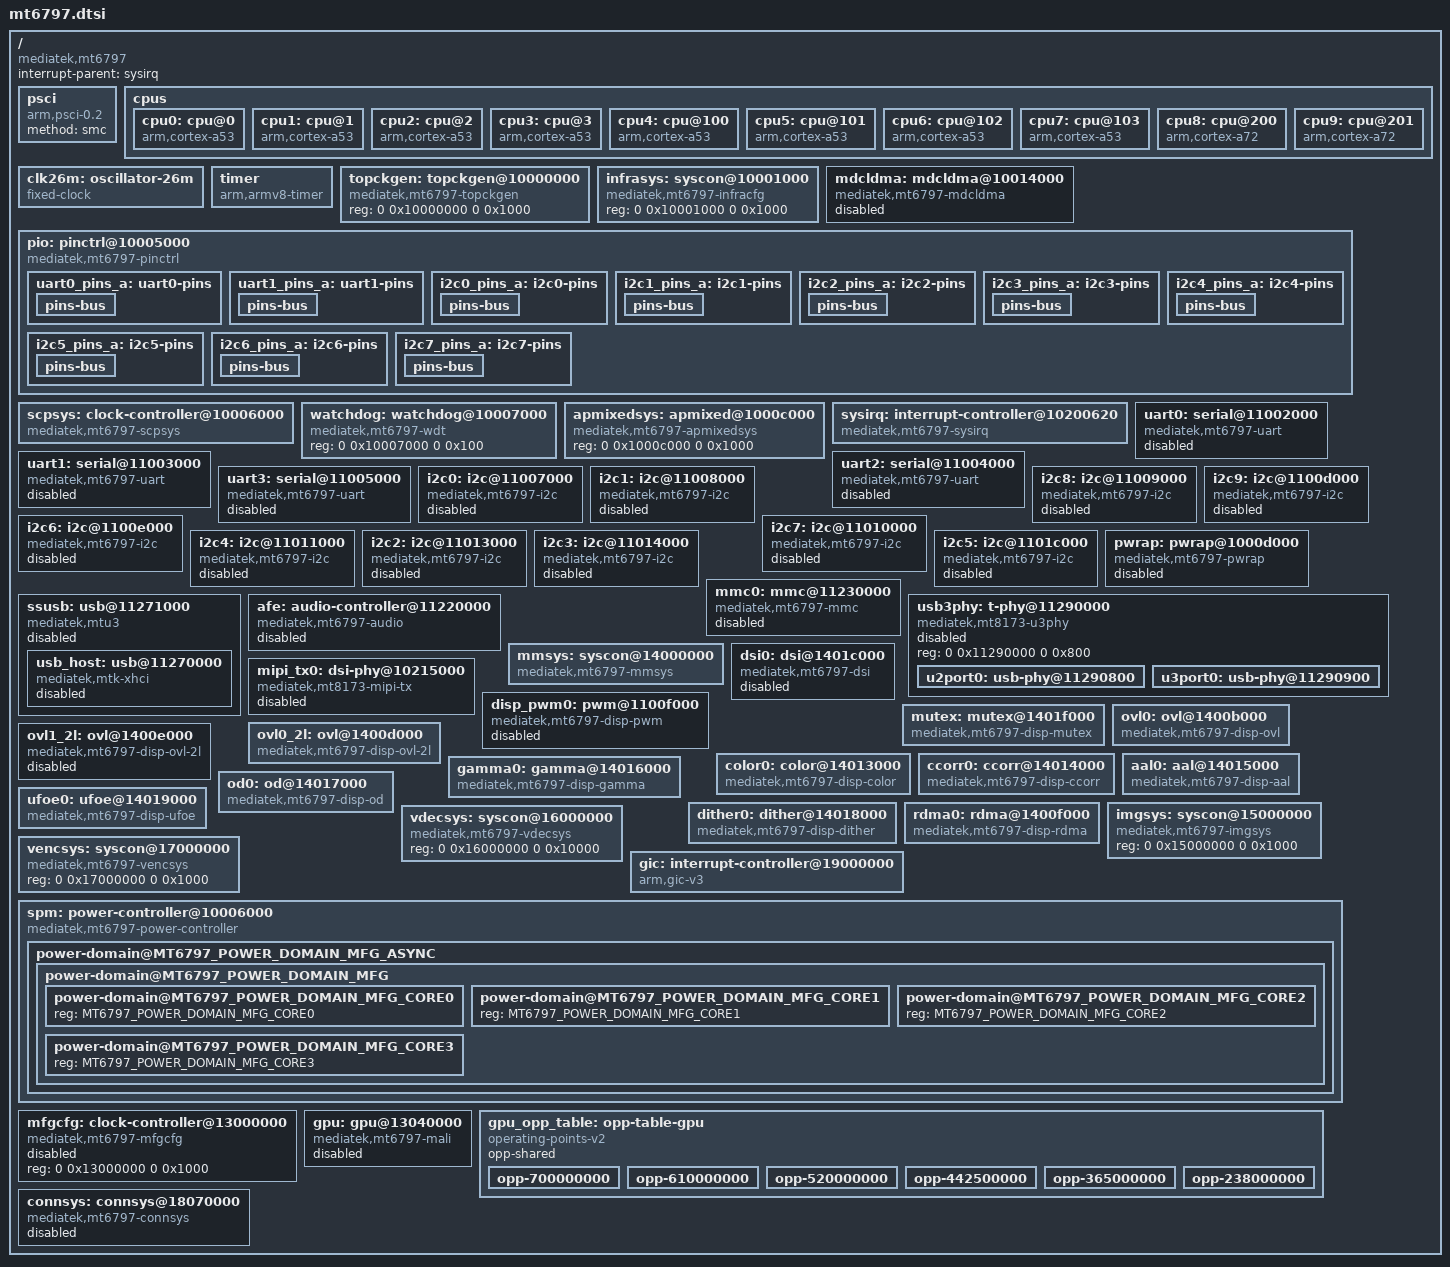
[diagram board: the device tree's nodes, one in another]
// SPDX-License-Identifier: GPL-2.0
/*
 * Copyright (c) 2017 MediaTek Inc.
 * Author: Mars.C <mars.cheng@mediatek.com>
 */

#include <dt-bindings/clock/mediatek,mt6797-mfgcfg.h>
#include <dt-bindings/clock/mt6797-clk.h>
#include <dt-bindings/interrupt-controller/irq.h>
#include <dt-bindings/interrupt-controller/arm-gic.h>
#include <dt-bindings/pinctrl/mt6797-pinfunc.h>
#include <dt-bindings/phy/phy.h>
#include <dt-bindings/power/mt6797-power.h>
#include <dt-bindings/reset/mt6797-resets.h>

/ {
	compatible = "mediatek,mt6797";
	interrupt-parent = <&sysirq>;
	#address-cells = <2>;
	#size-cells = <2>;

	psci {
		compatible = "arm,psci-0.2";
		method = "smc";
	};

	cpus {
		#address-cells = <1>;
		#size-cells = <0>;

		cpu0: cpu@0 {
			device_type = "cpu";
			compatible = "arm,cortex-a53";
			enable-method = "psci";
			reg = <0x000>;
		};

		cpu1: cpu@1 {
			device_type = "cpu";
			compatible = "arm,cortex-a53";
			enable-method = "psci";
			reg = <0x001>;
		};

		cpu2: cpu@2 {
			device_type = "cpu";
			compatible = "arm,cortex-a53";
			enable-method = "psci";
			reg = <0x002>;
		};

		cpu3: cpu@3 {
			device_type = "cpu";
			compatible = "arm,cortex-a53";
			enable-method = "psci";
			reg = <0x003>;
		};

		cpu4: cpu@100 {
			device_type = "cpu";
			compatible = "arm,cortex-a53";
			enable-method = "psci";
			reg = <0x100>;
		};

		cpu5: cpu@101 {
			device_type = "cpu";
			compatible = "arm,cortex-a53";
			enable-method = "psci";
			reg = <0x101>;
		};

		cpu6: cpu@102 {
			device_type = "cpu";
			compatible = "arm,cortex-a53";
			enable-method = "psci";
			reg = <0x102>;
		};

		cpu7: cpu@103 {
			device_type = "cpu";
			compatible = "arm,cortex-a53";
			enable-method = "psci";
			reg = <0x103>;
		};

		cpu8: cpu@200 {
			device_type = "cpu";
			compatible = "arm,cortex-a72";
			enable-method = "psci";
			reg = <0x200>;
		};

		cpu9: cpu@201 {
			device_type = "cpu";
			compatible = "arm,cortex-a72";
			enable-method = "psci";
			reg = <0x201>;
		};
	};

	clk26m: oscillator-26m {
		compatible = "fixed-clock";
		#clock-cells = <0>;
		clock-frequency = <26000000>;
		clock-output-names = "clk26m";
	};

	timer {
		compatible = "arm,armv8-timer";
		interrupt-parent = <&gic>;
		interrupts = <GIC_PPI 13 IRQ_TYPE_LEVEL_LOW>,
			     <GIC_PPI 14 IRQ_TYPE_LEVEL_LOW>,
			     <GIC_PPI 11 IRQ_TYPE_LEVEL_LOW>,
			     <GIC_PPI 10 IRQ_TYPE_LEVEL_LOW>;
	};

	topckgen: topckgen@10000000 {
		compatible = "mediatek,mt6797-topckgen";
		reg = <0 0x10000000 0 0x1000>;
		#clock-cells = <1>;
	};

	infrasys: syscon@10001000 {
		compatible = "mediatek,mt6797-infracfg", "syscon";
		reg = <0 0x10001000 0 0x1000>;
		#clock-cells = <1>;
		#reset-cells = <1>;
	};

	/*
	 * MD1 cellular modem: CLDMA DMA rings plus the CCIF doorbell.
	 * Register windows from the vendor 3.18 mt6797 DTS: CLDMA AO
	 * 0x10014000/0x10015000, CLDMA PD 0x10219000/0x1021a000, CCIF
	 * 0x10209000/0x1020a000, IRQ 265 (CLDMA), 147 (CCIF) and 266
	 * (MD watchdog).
	 */
	mdcldma: mdcldma@10014000 {
		compatible = "mediatek,mt6797-mdcldma";
		reg = <0 0x10014000 0 0x1e00>,	/* AP CLDMA AO */
		      <0 0x10015000 0 0x1e00>,	/* MD CLDMA AO */
		      <0 0x10219000 0 0x1e00>,	/* AP CLDMA PD */
		      <0 0x1021a000 0 0x1e00>,	/* MD CLDMA PD */
		      <0 0x10209000 0 0x1000>,	/* AP CCIF */
		      <0 0x1020a000 0 0x1000>;	/* MD CCIF */
		interrupts = <GIC_SPI 265 IRQ_TYPE_LEVEL_HIGH>,
			     <GIC_SPI 147 IRQ_TYPE_LEVEL_LOW>,
			     <GIC_SPI 266 IRQ_TYPE_EDGE_FALLING>;
		mediatek,md_id = <0>;
		mediatek,cldma_capability = <6>;
		mediatek,md_smem_size = <0x100000>;
		clocks = <&infrasys CLK_INFRA_CCIF_AP>,
			 <&infrasys CLK_INFRA_CCIF_MD>,
			 <&infrasys CLK_INFRA_CLDMA>;
		clock-names = "ccif-ap", "ccif-md", "cldma";
		status = "disabled";
	};

	pio: pinctrl@10005000 {
		compatible = "mediatek,mt6797-pinctrl";
		reg = <0 0x10005000 0 0x1000>,
		      <0 0x10002000 0 0x400>,
		      <0 0x10002400 0 0x400>,
		      <0 0x10002800 0 0x400>,
		      <0 0x10002C00 0 0x400>,
		      <0 0x1000b000 0 0x1000>;
		reg-names = "gpio", "iocfgl", "iocfgb",
			    "iocfgr", "iocfgt", "eint";
		gpio-controller;
		#gpio-cells = <2>;
		gpio-ranges = <&pio 0 0 262>;
		interrupt-controller;
		#interrupt-cells = <2>;
		#address-cells = <0>;
		interrupts = <GIC_SPI 170 IRQ_TYPE_LEVEL_HIGH>;

		uart0_pins_a: uart0-pins {
			pins-bus {
				pinmux = <MT6797_GPIO234__FUNC_UTXD0>,
					 <MT6797_GPIO235__FUNC_URXD0>;
			};
		};

		uart1_pins_a: uart1-pins {
			pins-bus {
				pinmux = <MT6797_GPIO232__FUNC_URXD1>,
					 <MT6797_GPIO233__FUNC_UTXD1>;
			};
		};

		i2c0_pins_a: i2c0-pins {
			pins-bus {
				pinmux = <MT6797_GPIO37__FUNC_SCL0_0>,
					 <MT6797_GPIO38__FUNC_SDA0_0>;
			};
		};

		i2c1_pins_a: i2c1-pins {
			pins-bus {
				pinmux = <MT6797_GPIO55__FUNC_SCL1_0>,
					 <MT6797_GPIO56__FUNC_SDA1_0>;
			};
		};

		i2c2_pins_a: i2c2-pins {
			pins-bus {
				pinmux = <MT6797_GPIO96__FUNC_SCL2_0>,
					 <MT6797_GPIO95__FUNC_SDA2_0>;
			};
		};

		i2c3_pins_a: i2c3-pins {
			pins-bus {
				pinmux = <MT6797_GPIO75__FUNC_SDA3_0>,
					 <MT6797_GPIO74__FUNC_SCL3_0>;
			};
		};

		i2c4_pins_a: i2c4-pins {
			pins-bus {
				pinmux = <MT6797_GPIO238__FUNC_SDA4_0>,
					 <MT6797_GPIO239__FUNC_SCL4_0>;
			};
		};

		i2c5_pins_a: i2c5-pins {
			pins-bus {
				pinmux = <MT6797_GPIO240__FUNC_SDA5_0>,
					 <MT6797_GPIO241__FUNC_SCL5_0>;
			};
		};

		i2c6_pins_a: i2c6-pins {
			pins-bus {
				pinmux = <MT6797_GPIO152__FUNC_SDA6_0>,
					 <MT6797_GPIO151__FUNC_SCL6_0>;
			};
		};

		i2c7_pins_a: i2c7-pins {
			pins-bus {
				pinmux = <MT6797_GPIO154__FUNC_SDA7_0>,
					 <MT6797_GPIO153__FUNC_SCL7_0>;
			};
		};
	};

	/*
	 * Legacy MT6797 clock/power-controller node: not a genpd provider
	 * (that is "spm", mt6797-power-controller, further down this file),
	 * it only backs the power-domain-cells phandle on mmsys. Unit
	 * address renamed so it no longer collides with the SPM genpd node.
	 */
	scpsys: clock-controller@10006000 {
		compatible = "mediatek,mt6797-scpsys";
		#power-domain-cells = <1>;
		reg = <0 0x10006000 0 0x1000>;
		clocks = <&topckgen CLK_TOP_MUX_MFG>,
			 <&topckgen CLK_TOP_MUX_MM>,
			 <&topckgen CLK_TOP_MUX_VDEC>;
		clock-names = "mfg", "mm", "vdec";
		infracfg = <&infrasys>;
	};

	watchdog: watchdog@10007000 {
		compatible = "mediatek,mt6797-wdt", "mediatek,mt6589-wdt";
		reg = <0 0x10007000 0 0x100>;
	};

	apmixedsys: apmixed@1000c000 {
		compatible = "mediatek,mt6797-apmixedsys";
		reg = <0 0x1000c000 0 0x1000>;
		#clock-cells = <1>;
	};

	sysirq: interrupt-controller@10200620 {
		compatible = "mediatek,mt6797-sysirq",
			     "mediatek,mt6577-sysirq";
		interrupt-controller;
		#interrupt-cells = <3>;
		interrupt-parent = <&gic>;
		reg = <0 0x10220620 0 0x20>,
		      <0 0x10220690 0 0x10>;
	};

	uart0: serial@11002000 {
		compatible = "mediatek,mt6797-uart",
			     "mediatek,mt6577-uart";
		reg = <0 0x11002000 0 0x400>;
		interrupts = <GIC_SPI 91 IRQ_TYPE_LEVEL_LOW>;
		clocks = <&infrasys CLK_INFRA_UART0>,
			 <&infrasys CLK_INFRA_AP_DMA>;
		clock-names = "baud", "bus";
		status = "disabled";
	};

	uart1: serial@11003000 {
		compatible = "mediatek,mt6797-uart",
			     "mediatek,mt6577-uart";
		reg = <0 0x11003000 0 0x400>;
		interrupts = <GIC_SPI 92 IRQ_TYPE_LEVEL_LOW>;
		clocks = <&infrasys CLK_INFRA_UART1>,
			 <&infrasys CLK_INFRA_AP_DMA>;
		clock-names = "baud", "bus";
		status = "disabled";
	};

	uart2: serial@11004000 {
		compatible = "mediatek,mt6797-uart",
			     "mediatek,mt6577-uart";
		reg = <0 0x11004000 0 0x400>;
		interrupts = <GIC_SPI 93 IRQ_TYPE_LEVEL_LOW>;
		clocks = <&infrasys CLK_INFRA_UART2>,
			 <&infrasys CLK_INFRA_AP_DMA>;
		clock-names = "baud", "bus";
		status = "disabled";
	};

	uart3: serial@11005000 {
		compatible = "mediatek,mt6797-uart",
			     "mediatek,mt6577-uart";
		reg = <0 0x11005000 0 0x400>;
		interrupts = <GIC_SPI 94 IRQ_TYPE_LEVEL_LOW>;
		clocks = <&infrasys CLK_INFRA_UART3>,
			 <&infrasys CLK_INFRA_AP_DMA>;
		clock-names = "baud", "bus";
		status = "disabled";
	};

	i2c0: i2c@11007000 {
		compatible = "mediatek,mt6797-i2c",
			     "mediatek,mt6577-i2c";
		reg = <0 0x11007000 0 0x1000>,
		      <0 0x11000100 0 0x80>;
		interrupts = <GIC_SPI 84 IRQ_TYPE_LEVEL_LOW>;
		clocks = <&infrasys CLK_INFRA_I2C0>,
			 <&infrasys CLK_INFRA_AP_DMA>;
		clock-names = "main", "dma";
		clock-div = <10>;
		#address-cells = <1>;
		#size-cells = <0>;
		status = "disabled";
	};

	i2c1: i2c@11008000 {
		compatible = "mediatek,mt6797-i2c",
			     "mediatek,mt6577-i2c";
		reg = <0 0x11008000 0 0x1000>,
		      <0 0x11000180 0 0x80>;
		interrupts = <GIC_SPI 85 IRQ_TYPE_LEVEL_LOW>;
		clocks = <&infrasys CLK_INFRA_I2C1>,
			 <&infrasys CLK_INFRA_AP_DMA>;
		clock-names = "main", "dma";
		clock-div = <10>;
		#address-cells = <1>;
		#size-cells = <0>;
		status = "disabled";
	};

	i2c8: i2c@11009000 {
		compatible = "mediatek,mt6797-i2c",
			     "mediatek,mt6577-i2c";
		reg = <0 0x11009000 0 0x1000>,
		      <0 0x11000200 0 0x80>;
		interrupts = <GIC_SPI 86 IRQ_TYPE_LEVEL_LOW>;
		clocks = <&infrasys CLK_INFRA_I2C2>,
			 <&infrasys CLK_INFRA_AP_DMA>,
			 <&infrasys CLK_INFRA_I2C2_ARB>;
		clock-names = "main", "dma", "arb";
		clock-div = <10>;
		#address-cells = <1>;
		#size-cells = <0>;
		status = "disabled";
	};

	i2c9: i2c@1100d000 {
		compatible = "mediatek,mt6797-i2c",
			     "mediatek,mt6577-i2c";
		reg = <0 0x1100d000 0 0x1000>,
		      <0 0x11000280 0 0x80>;
		interrupts = <GIC_SPI 87 IRQ_TYPE_LEVEL_LOW>;
		clocks = <&infrasys CLK_INFRA_I2C3>,
			 <&infrasys CLK_INFRA_AP_DMA>,
			 <&infrasys CLK_INFRA_I2C3_ARB>;
		clock-names = "main", "dma", "arb";
		clock-div = <10>;
		#address-cells = <1>;
		#size-cells = <0>;
		status = "disabled";
	};

	i2c6: i2c@1100e000 {
		compatible = "mediatek,mt6797-i2c",
			     "mediatek,mt6577-i2c";
		reg = <0 0x1100e000 0 0x1000>,
		      <0 0x11000500 0 0x80>;
		interrupts = <GIC_SPI 88 IRQ_TYPE_LEVEL_LOW>;
		clocks = <&infrasys CLK_INFRA_I2C_APPM>,
			 <&infrasys CLK_INFRA_AP_DMA>;
		clock-names = "main", "dma";
		clock-div = <10>;
		#address-cells = <1>;
		#size-cells = <0>;
		status = "disabled";
	};

	i2c7: i2c@11010000 {
		compatible = "mediatek,mt6797-i2c",
			     "mediatek,mt6577-i2c";
		reg = <0 0x11010000 0 0x1000>,
		      <0 0x11000580 0 0x80>;
		interrupts = <GIC_SPI 89 IRQ_TYPE_LEVEL_LOW>;
		clocks = <&infrasys CLK_INFRA_I2C_GPUPM>,
			 <&infrasys CLK_INFRA_AP_DMA>;
		clock-names = "main", "dma";
		clock-div = <10>;
		#address-cells = <1>;
		#size-cells = <0>;
		status = "disabled";
	};

	i2c4: i2c@11011000 {
		compatible = "mediatek,mt6797-i2c",
			     "mediatek,mt6577-i2c";
		reg = <0 0x11011000 0 0x1000>,
		      <0 0x11000300 0 0x80>;
		interrupts = <GIC_SPI 90 IRQ_TYPE_LEVEL_LOW>;
		clocks = <&infrasys CLK_INFRA_I2C4>,
			 <&infrasys CLK_INFRA_AP_DMA>;
		clock-names = "main", "dma";
		clock-div = <10>;
		#address-cells = <1>;
		#size-cells = <0>;
		status = "disabled";
	};

	i2c2: i2c@11013000 {
		compatible = "mediatek,mt6797-i2c",
			     "mediatek,mt6577-i2c";
		reg = <0 0x11013000 0 0x1000>,
		      <0 0x11000400 0 0x80>;
		interrupts = <GIC_SPI 95 IRQ_TYPE_LEVEL_LOW>;
		clocks = <&infrasys CLK_INFRA_I2C2_IMM>,
			 <&infrasys CLK_INFRA_AP_DMA>,
			 <&infrasys CLK_INFRA_I2C2_ARB>;
		clock-names = "main", "dma", "arb";
		clock-div = <10>;
		#address-cells = <1>;
		#size-cells = <0>;
		status = "disabled";
	};

	i2c3: i2c@11014000 {
		compatible = "mediatek,mt6797-i2c",
			     "mediatek,mt6577-i2c";
		reg = <0 0x11014000 0 0x1000>,
		      <0 0x11000480 0 0x80>;
		interrupts = <GIC_SPI 96 IRQ_TYPE_LEVEL_LOW>;
		clocks = <&infrasys CLK_INFRA_I2C3_IMM>,
			 <&infrasys CLK_INFRA_AP_DMA>,
			 <&infrasys CLK_INFRA_I2C3_ARB>;
		clock-names = "main", "dma", "arb";
		clock-div = <10>;
		#address-cells = <1>;
		#size-cells = <0>;
		status = "disabled";
	};

	i2c5: i2c@1101c000 {
		compatible = "mediatek,mt6797-i2c",
			     "mediatek,mt6577-i2c";
		reg = <0 0x1101c000 0 0x1000>,
		      <0 0x11000380 0 0x80>;
		interrupts = <GIC_SPI 83 IRQ_TYPE_LEVEL_LOW>;
		clocks = <&infrasys CLK_INFRA_I2C5>,
			 <&infrasys CLK_INFRA_AP_DMA>;
		clock-names = "main", "dma";
		clock-div = <10>;
		#address-cells = <1>;
		#size-cells = <0>;
		status = "disabled";
	};

	/*
	 * PMIC wrapper. MT6797 uses the same register layout as MT6755/MT6797
	 * (pwrap_mt6797 in the driver); the wrapper is brought up by LK, so
	 * Linux only needs the regmap for the MT6351 child.
	 */
	pwrap: pwrap@1000d000 {
		compatible = "mediatek,mt6797-pwrap";
		reg = <0 0x1000d000 0 0x1000>;
		reg-names = "pwrap";
		interrupts = <GIC_SPI 178 IRQ_TYPE_LEVEL_HIGH>;
		clocks = <&topckgen CLK_TOP_MUX_PMICSPI>,
			 <&infrasys CLK_INFRA_PMIC_AP>;
		clock-names = "spi", "wrap";
		resets = <&infrasys MT6797_INFRA_PMIC_WRAP_RST>;
		reset-names = "pwrap";
		status = "disabled";
	};

	mmc0: mmc@11230000 {
		compatible = "mediatek,mt6797-mmc";
		reg = <0 0x11230000 0 0x10000>;
		interrupts = <GIC_SPI 79 IRQ_TYPE_LEVEL_LOW>;
		clocks = <&topckgen CLK_TOP_MUX_MSDC50_0>,
			 <&topckgen CLK_TOP_MUX_MSDC50_0_HCLK>,
			 <&infrasys CLK_INFRA_MSDC0>;
		clock-names = "source", "hclk", "source_cg";
		status = "disabled";
	};

	/*
	 * MT6797 SSUSB: MUSB device core plus xHCI host behind the IPPC glue.
	 *
	 * Addresses come from the vendor DTS reg-names combined with the vendor
	 * HAL register map:
	 *   vendor DTS usb0/usb3@11270000 reg-names
	 *     ssusb_base 0x11270000, ssusb_sif 0x11280000, ssusb_sif2 0x11290000
	 *   mu3d/hal/mu3d_hal_hw.h
	 *     SSUSB_DEV_BASE         = u3_base     + 0x1000  (line 126)
	 *     SSUSB_SIFSLV_IPPC_BASE = u3_sif_base + 0x700   (line 135)
	 *   => mac 0x11271000, ippc 0x11280700.
	 * Device interrupt is GIC_SPI 127 ("musb-hdrc" in the vendor DTS),
	 * host (xHCI) interrupt is GIC_SPI 126 ("xhci").
	 *
	 * There is no MT6797 entry in the mtu3 or T-PHY match tables, so the
	 * generic "mediatek,mtu3" and the mt8173/v1 T-PHY data are used; the
	 * register layout is the same v1 SSUSB block as mt6755/mt8173.
	 */
	ssusb: usb@11271000 {
		compatible = "mediatek,mtu3";
		reg = <0 0x11271000 0 0x3000>,
		      <0 0x11280700 0 0x100>;
		reg-names = "mac", "ippc";
		interrupts = <GIC_SPI 127 IRQ_TYPE_LEVEL_LOW>;
		phys = <&u2port0 PHY_TYPE_USB2>,
		       <&u3port0 PHY_TYPE_USB3>;
		clocks = <&infrasys CLK_INFRA_ICUSB>,
			 <&infrasys CLK_INFRA_SSUSB_REF>;
		clock-names = "sys_ck", "ref_ck";
		#address-cells = <2>;
		#size-cells = <2>;
		ranges;
		status = "disabled";

		usb_host: usb@11270000 {
			compatible = "mediatek,mtk-xhci";
			reg = <0 0x11270000 0 0x1000>;
			reg-names = "mac";
			interrupts = <GIC_SPI 126 IRQ_TYPE_LEVEL_LOW>;
			clocks = <&infrasys CLK_INFRA_ICUSB>,
				 <&infrasys CLK_INFRA_SSUSB_REF>;
			clock-names = "sys_ck", "ref_ck";
			status = "disabled";
		};
	};

	/*
	 * MT6797 SSUSB T-PHY, mt8173 (v1) register layout. All banks live in
	 * the second SIF (0x11290000), mu3d/hal/mu3d_hal_hw.h:141-147:
	 *   +0x000 SPLLC, +0x100 U2FREQ, +0x300 chip, +0x800 U2PHY_COM,
	 *   +0x900 U3PHYD, +0xb00 U3PHYA (U3PHYA = PHYD + 0x200 in tphy v1).
	 */
	usb3phy: t-phy@11290000 {
		compatible = "mediatek,mt8173-u3phy";
		reg = <0 0x11290000 0 0x800>;
		#address-cells = <2>;
		#size-cells = <2>;
		ranges;
		status = "disabled";

		u2port0: usb-phy@11290800 {
			reg = <0 0x11290800 0 0x100>;
			clocks = <&topckgen CLK_TOP_SSUSB_PHY_48M_CK>;
			clock-names = "ref";
			#phy-cells = <1>;
		};

		u3port0: usb-phy@11290900 {
			reg = <0 0x11290900 0 0x700>;
			clocks = <&clk26m>;
			clock-names = "ref";
			#phy-cells = <1>;
		};
	};

	afe: audio-controller@11220000 {
		compatible = "mediatek,mt6797-audio";
		reg = <0 0x11220000 0 0x1000>;
		interrupts = <GIC_SPI 151 IRQ_TYPE_LEVEL_LOW>;
		power-domains = <&scpsys MT6797_POWER_DOMAIN_AUDIO>;
		clocks = <&infrasys CLK_INFRA_AUDIO>,
			 <&infrasys CLK_INFRA_AUDIO_26M>,
			 <&infrasys CLK_INFRA_AUDIO_26M_PAD_TOP>,
			 <&topckgen CLK_TOP_MUX_AUDIO>,
			 <&topckgen CLK_TOP_MUX_AUD_INTBUS>,
			 <&topckgen CLK_TOP_SYSPLL3_D4>,
			 <&topckgen CLK_TOP_SYSPLL1_D4>,
			 <&clk26m>;
		clock-names = "infra_sys_audio_clk", "infra_sys_audio_26m",
			      "mtkaif_26m_clk", "top_mux_audio",
			      "top_mux_aud_intbus", "top_sys_pll3_d4",
			      "top_sys_pll1_d4", "top_clk26m_clk";
		status = "disabled";
	};

	mmsys: syscon@14000000 {
		compatible = "mediatek,mt6797-mmsys", "syscon";
		reg = <0 0x14000000 0 0x1000>;
		#clock-cells = <1>;
		/*
		 * The MMSYS block (and every DISP register behind it) lives in
		 * the MT6797 "MM" MTCMOS domain; touching it while the domain
		 * is off hangs the bus. Same arrangement as mt6755.
		 */
		power-domains = <&scpsys MT6797_POWER_DOMAIN_MM>;
	};

	/*
	 * MT6797 DSI0 and its MIPI TX PHY.
	 *
	 * Base address and interrupt from the vendor dispsys node
	 * (arch/arm64/boot/dts/mt6797.dtsi): <0x1401c000 0x1000> "disp_dsi0",
	 * GIC_SPI 229. The controller register layout is mt8173-compatible
	 * (see mt6797_dsi_driver_data in mtk_dsi.c).
	 *
	 * Clocks are the two MMSYS DSI0 gates that clk-mt6797-mm.c already
	 * implements: CLK_MM_DSI0_MM_CLOCK (33) and
	 * CLK_MM_DSI0_INTERFACE_CLOCK (41), plus the MIPI TX PLL.
	 *
	 * MIPITX0 sits at 0x10215000 (vendor "mipi_tx0@10215000") on the
	 * infra bus, outside the DISP domain, and its bank layout matches
	 * mt8173 (vendor ddp_reg.h:1003-1030: CON 0x00, CLOCK/DATA lanes
	 * 0x04-0x14, TOP_CON 0x40, BG_CON 0x44, PLL_CON0-3 0x50-0x5c,
	 * PLL_CHG 0x60, PLL_TOP 0x64, PLL_PWR 0x68, SW_CTRL 0x80).
	 */
	dsi0: dsi@1401c000 {
		compatible = "mediatek,mt6797-dsi", "mediatek,mt8173-dsi";
		reg = <0 0x1401c000 0 0x1000>;
		interrupts = <GIC_SPI 229 IRQ_TYPE_LEVEL_LOW>;
		clocks = <&mmsys CLK_MM_DSI0_MM_CLOCK>,
			 <&mmsys CLK_MM_DSI0_INTERFACE_CLOCK>,
			 <&mipi_tx0>;
		clock-names = "engine", "digital", "hs";
		phys = <&mipi_tx0>;
		phy-names = "dphy";
		power-domains = <&scpsys MT6797_POWER_DOMAIN_MM>;
		#address-cells = <1>;
		#size-cells = <0>;
		status = "disabled";
	};

	mipi_tx0: dsi-phy@10215000 {
		compatible = "mediatek,mt8173-mipi-tx";
		reg = <0 0x10215000 0 0x1000>;
		clocks = <&clk26m>;
		clock-output-names = "mipi_tx0_pll";
		#clock-cells = <0>;
		#phy-cells = <0>;
		status = "disabled";
	};

	/*
	 * MT6797 display PWM (backlight).  The vendor pwm_disp@1100f000 node
	 * only gives the address; the register layout is pinned by
	 * video/mt6797/dispsys/ddp_reg.h:1309-1312 —
	 *   DISP_PWM_EN_OFF 0x00, DISP_PWM_COMMIT_OFF 0x08,
	 *   DISP_PWM_CON_0_OFF 0x10, DISP_PWM_CON_1_OFF 0x14 —
	 * and by ddp_pwm.c, which writes the divider to CON_0 bits 16-25,
	 * the source select to CON_0 bits 4-5, and period | duty << 16 to
	 * CON_1.  That is exactly the mt8173 layout, so the mt8173 driver
	 * data applies.
	 *
	 * The block sits on the infra bus at 0x1100f000 and is gated by a
	 * single CLK_INFRA_DISP_PWM (parent pwm_sel); the driver wants a
	 * "main" and a "mm" clock, so both names resolve to that one gate.
	 * Neither the vendor DTS nor the driver pins the pwm_sel parent.
	 */
	disp_pwm0: pwm@1100f000 {
		compatible = "mediatek,mt6797-disp-pwm",
			     "mediatek,mt8173-disp-pwm";
		reg = <0 0x1100f000 0 0x1000>;
		#pwm-cells = <2>;
		clocks = <&infrasys CLK_INFRA_DISP_PWM>,
			 <&infrasys CLK_INFRA_DISP_PWM>;
		clock-names = "main", "mm";
		status = "disabled";
	};

	/*
	 * MT6797 DDP blocks used by the primary display path.
	 *
	 * Addresses and interrupts are taken verbatim from the vendor dispsys
	 * node (arch/arm64/boot/dts/mt6797.dtsi): ovl0 0x1400b000/SPI 213,
	 * ovl0_2l 0x1400d000/SPI 215, ovl1_2l 0x1400e000/SPI 216,
	 * rdma0 0x1400f000/SPI 217, color 0x14013000/SPI 221,
	 * ccorr 0x14014000/SPI 222, aal 0x14015000/SPI 223,
	 * gamma 0x14016000/SPI 224, od 0x14017000/SPI 225,
	 * dither 0x14018000/SPI 226, ufoe 0x14019000/SPI 227,
	 * mutex 0x1401f000/SPI 202.
	 *
	 * Register layouts were checked against the vendor ddp_reg.h and are
	 * the mt8173/mt8183 generations noted per node.
	 */
	mutex: mutex@1401f000 {
		compatible = "mediatek,mt6797-disp-mutex";
		reg = <0 0x1401f000 0 0x1000>;
		interrupts = <GIC_SPI 202 IRQ_TYPE_LEVEL_LOW>;
		power-domains = <&scpsys MT6797_POWER_DOMAIN_MM>;
	};

	ovl0: ovl@1400b000 {
		/* L0_ADDR at 0xf40 (ddp_reg.h:2134) == mt8173 OVL. */
		compatible = "mediatek,mt6797-disp-ovl",
			     "mediatek,mt8173-disp-ovl";
		reg = <0 0x1400b000 0 0x1000>;
		interrupts = <GIC_SPI 213 IRQ_TYPE_LEVEL_LOW>;
		clocks = <&mmsys CLK_MM_DISP_OVL0>;
		power-domains = <&scpsys MT6797_POWER_DOMAIN_MM>;
	};

	ovl0_2l: ovl@1400d000 {
		/*
		 * 2-layer overlay stage of the MT6797 OVL cascade. Layer
		 * registers use the same 0xf40 L0_ADDR layout; the only
		 * 2-layer in-tree variant with that layout is the mt8183 one
		 * (gmc_bits differs, unverified for MT6797).
		 */
		compatible = "mediatek,mt6797-disp-ovl-2l",
			     "mediatek,mt8183-disp-ovl-2l";
		reg = <0 0x1400d000 0 0x1000>;
		interrupts = <GIC_SPI 215 IRQ_TYPE_LEVEL_LOW>;
		clocks = <&mmsys CLK_MM_DISP_OVL0_2L>;
		power-domains = <&scpsys MT6797_POWER_DOMAIN_MM>;
	};

	ovl1_2l: ovl@1400e000 {
		/* Not in the two-stage cascade used by mtk-drm (see mmsys). */
		compatible = "mediatek,mt6797-disp-ovl-2l",
			     "mediatek,mt8183-disp-ovl-2l";
		reg = <0 0x1400e000 0 0x1000>;
		interrupts = <GIC_SPI 216 IRQ_TYPE_LEVEL_LOW>;
		clocks = <&mmsys CLK_MM_DISP_OVL1_2L>;
		power-domains = <&scpsys MT6797_POWER_DOMAIN_MM>;
		status = "disabled";
	};

	color0: color@14013000 {
		/* CFG_MAIN 0x400 / START 0xc00 (ddp_reg.h:1331,1385) == mt8173. */
		compatible = "mediatek,mt6797-disp-color",
			     "mediatek,mt8173-disp-color";
		reg = <0 0x14013000 0 0x1000>;
		interrupts = <GIC_SPI 221 IRQ_TYPE_LEVEL_LOW>;
		clocks = <&mmsys CLK_MM_DISP_COLOR>;
		power-domains = <&scpsys MT6797_POWER_DOMAIN_MM>;
	};

	ccorr0: ccorr@14014000 {
		/* EN 0x00 / CFG 0x20 / SIZE 0x30 / COEF_0 0x80 == mt8183. */
		compatible = "mediatek,mt6797-disp-ccorr",
			     "mediatek,mt8183-disp-ccorr";
		reg = <0 0x14014000 0 0x1000>;
		interrupts = <GIC_SPI 222 IRQ_TYPE_LEVEL_LOW>;
		clocks = <&mmsys CLK_MM_DISP_CCORR>;
		power-domains = <&scpsys MT6797_POWER_DOMAIN_MM>;
	};

	aal0: aal@14015000 {
		/* EN 0x00 / CFG 0x20 / SIZE 0x30 (ddp_reg.h:1283-1292) == mt8173. */
		compatible = "mediatek,mt6797-disp-aal",
			     "mediatek,mt8173-disp-aal";
		reg = <0 0x14015000 0 0x1000>;
		interrupts = <GIC_SPI 223 IRQ_TYPE_LEVEL_LOW>;
		clocks = <&mmsys CLK_MM_DISP_AAL>;
		power-domains = <&scpsys MT6797_POWER_DOMAIN_MM>;
	};

	gamma0: gamma@14016000 {
		/* EN 0x00 / CFG 0x20 / SIZE 0x30 / LUT 0x700 == mt8173. */
		compatible = "mediatek,mt6797-disp-gamma",
			     "mediatek,mt8173-disp-gamma";
		reg = <0 0x14016000 0 0x1000>;
		interrupts = <GIC_SPI 224 IRQ_TYPE_LEVEL_LOW>;
		clocks = <&mmsys CLK_MM_DISP_GAMMA>;
		power-domains = <&scpsys MT6797_POWER_DOMAIN_MM>;
	};

	od0: od@14017000 {
		compatible = "mediatek,mt6797-disp-od",
			     "mediatek,mt8173-disp-od";
		reg = <0 0x14017000 0 0x1000>;
		interrupts = <GIC_SPI 225 IRQ_TYPE_LEVEL_LOW>;
		clocks = <&mmsys CLK_MM_DISP_OD>;
		power-domains = <&scpsys MT6797_POWER_DOMAIN_MM>;
	};

	dither0: dither@14018000 {
		/* EN 0x00 / CFG 0x20 / SIZE 0x30 (ddp_reg.h:1928-1937) == mt8183. */
		compatible = "mediatek,mt6797-disp-dither",
			     "mediatek,mt8183-disp-dither";
		reg = <0 0x14018000 0 0x1000>;
		interrupts = <GIC_SPI 226 IRQ_TYPE_LEVEL_LOW>;
		clocks = <&mmsys CLK_MM_DISP_DITHER>;
		power-domains = <&scpsys MT6797_POWER_DOMAIN_MM>;
	};

	ufoe0: ufoe@14019000 {
		/*
		 * MT6797 routes every DSI output through UFOE; a single-DSI
		 * video panel only needs the block in bypass mode, which is
		 * all mtk-drm's UFOE component does (UFO_BYPASS).
		 */
		compatible = "mediatek,mt6797-disp-ufoe",
			     "mediatek,mt8173-disp-ufoe";
		reg = <0 0x14019000 0 0x1000>;
		interrupts = <GIC_SPI 227 IRQ_TYPE_LEVEL_LOW>;
		clocks = <&mmsys CLK_MM_DISP_UFOE>;
		power-domains = <&scpsys MT6797_POWER_DOMAIN_MM>;
	};

	rdma0: rdma@1400f000 {
		/* MEM_START_ADDR 0xf00 (ddp_reg.h:2431) == mt8173, 8 KiB FIFO. */
		compatible = "mediatek,mt6797-disp-rdma",
			     "mediatek,mt8173-disp-rdma";
		reg = <0 0x1400f000 0 0x1000>;
		interrupts = <GIC_SPI 217 IRQ_TYPE_LEVEL_LOW>;
		clocks = <&mmsys CLK_MM_DISP_RDMA0>;
		power-domains = <&scpsys MT6797_POWER_DOMAIN_MM>;
	};

	imgsys: syscon@15000000  {
		compatible = "mediatek,mt6797-imgsys", "syscon";
		reg = <0 0x15000000 0 0x1000>;
		#clock-cells = <1>;
	};

	vdecsys: syscon@16000000 {
		compatible = "mediatek,mt6797-vdecsys", "syscon";
		reg = <0 0x16000000 0 0x10000>;
		#clock-cells = <1>;
	};

	vencsys: syscon@17000000 {
		compatible = "mediatek,mt6797-vencsys", "syscon";
		reg = <0 0x17000000 0 0x1000>;
		#clock-cells = <1>;
	};

	gic: interrupt-controller@19000000 {
		compatible = "arm,gic-v3";
		#interrupt-cells = <3>;
		interrupt-parent = <&gic>;
		interrupts = <GIC_PPI 9 IRQ_TYPE_LEVEL_HIGH>;
		interrupt-controller;
		reg = <0 0x19000000 0 0x10000>,    /* GICD */
		      <0 0x19200000 0 0x200000>,   /* GICR */
		      <0 0x10240000 0 0x2000>;     /* GICC */
	};
	/*
	 * Mali-T880MP4 GPU support.
	 *
	 * The original "mediatek,mt6797-scpsys" node (above, label scpsys,
	 * kept for the MM/MMSYS power-domain phandles) is driver-less: the
	 * kernel binds the genpd provider through "mediatek,mt6797-power-controller"
	 * (drivers/pmdomain/mediatek/mt6797-pm-domains.h). The GPU needs the
	 * nested MTCMOS hierarchy MFG_ASYNC -> MFG -> MFG_CORE0..3, so this
	 * spm node exposes exactly those five domains of the same SPM block.
	 *
	 * VERIFIED-FROM-STOCK (kernel-m685-3.18 arch/arm64/boot/dts/
	 * mt6797.dtsi:3007-3056 and drivers/misc/mediatek/base/power/include/
	 * spm_v2/mt_spm_reg_mt6797.h): MFG_ASYNC 0x334, MFG 0x338,
	 * MFG_CORE0..3 0x340..0x34c, PWR_STATUS 0x180; mfgcfg g3d_config at
	 * 0x13000000, mali@13040000 with SPI 264 (JOB) / 263 (MMU) / 262
	 * (GPU) LEVEL_LOW; the stock GPU DVFS table is
	 * mt_gpufreq_opp_tbl_e1_0[] = 700 / 610 / 520 / 442.5 / 365 / 238 MHz
	 * (mt_gpufreq.c:128-172, 281-288).
	 */
	spm: power-controller@10006000 {
		compatible = "mediatek,mt6797-power-controller";
		reg = <0 0x10006000 0 0x1000>;
		#address-cells = <1>;
		#size-cells = <0>;
		#power-domain-cells = <1>;
		access-controllers = <&infrasys>;
		mediatek,infracfg = <&infrasys>;

		power-domain@MT6797_POWER_DOMAIN_MFG_ASYNC {
			reg = <MT6797_POWER_DOMAIN_MFG_ASYNC>;
			#address-cells = <1>;
			#size-cells = <0>;
			#power-domain-cells = <0>;
			mediatek,infracfg = <&infrasys>;

			power-domain@MT6797_POWER_DOMAIN_MFG {
				reg = <MT6797_POWER_DOMAIN_MFG>;
				#address-cells = <1>;
				#size-cells = <0>;
				#power-domain-cells = <0>;
				mediatek,infracfg = <&infrasys>;

				power-domain@MT6797_POWER_DOMAIN_MFG_CORE0 {
					reg = <MT6797_POWER_DOMAIN_MFG_CORE0>;
					#power-domain-cells = <0>;
				};

				power-domain@MT6797_POWER_DOMAIN_MFG_CORE1 {
					reg = <MT6797_POWER_DOMAIN_MFG_CORE1>;
					#power-domain-cells = <0>;
				};

				power-domain@MT6797_POWER_DOMAIN_MFG_CORE2 {
					reg = <MT6797_POWER_DOMAIN_MFG_CORE2>;
					#power-domain-cells = <0>;
				};

				power-domain@MT6797_POWER_DOMAIN_MFG_CORE3 {
					reg = <MT6797_POWER_DOMAIN_MFG_CORE3>;
					#power-domain-cells = <0>;
				};
			};
		};
	};

	/*
	 * mfgcfg clock gate. Registers inertly: mfgcfg lives in the
	 * MFG_ASYNC MTCMOS domain and is brought up by the GPU consumer
	 * (panfrost, through the "mfg" power domain) before it enables
	 * BG3D. See drivers/clk/mediatek/clk-mt6797-mfg.c.
	 */
	mfgcfg: clock-controller@13000000 {
		compatible = "mediatek,mt6797-mfgcfg";
		reg = <0 0x13000000 0 0x1000>;
		#clock-cells = <1>;
		status = "disabled";
	};

	gpu: gpu@13040000 {
		compatible = "mediatek,mt6797-mali", "arm,mali-t880",
			     "arm,mali-midgard";
		reg = <0 0x13040000 0 0x4000>;
		interrupts = <GIC_SPI 264 IRQ_TYPE_LEVEL_LOW>,
			     <GIC_SPI 263 IRQ_TYPE_LEVEL_LOW>,
			     <GIC_SPI 262 IRQ_TYPE_LEVEL_LOW>;
		interrupt-names = "job", "mmu", "gpu";
		clocks = <&mfgcfg CLK_MFG_BG3D>;
		clock-names = "core";
		clock-frequency = <700000000>;
		power-domains = <&spm MT6797_POWER_DOMAIN_MFG>;
		operating-points-v2 = <&gpu_opp_table>;
		status = "disabled";
	};

	/*
	 * GPU DVFS table, stock MX6 "freq_table_type = 0" profile
	 * (mt_gpufreq.c:281-288): 700/610/520/442.5/365/238 MHz with the
	 * vendor Vcore-mapped voltages. The MX6 VGPU rail is an external I2C
	 * buck (rt5735@i2c7:0x1c / fan53200@i2c7:0x60, the "VGPU Buck" block
	 * of the stock DTS, VGPU_SET_BY_EXTIC in mt_gpufreq.c) whose
	 * regulator driver is not in mainline, so no OPP regulator is
	 * attached and devfreq only retunes mfg_sel.
	 */
	gpu_opp_table: opp-table-gpu {
		compatible = "operating-points-v2";
		opp-shared;

		opp-700000000 {
			opp-hz = /bits/ 64 <700000000>;
			opp-microvolt = <1090400>;
		};

		opp-610000000 {
			opp-hz = /bits/ 64 <610000000>;
			opp-microvolt = <1039100>;
		};

		opp-520000000 {
			opp-hz = /bits/ 64 <520000000>;
			opp-microvolt = <1000600>;
		};

		opp-442500000 {
			opp-hz = /bits/ 64 <442500000>;
			opp-microvolt = <949300>;
		};

		opp-365000000 {
			opp-hz = /bits/ 64 <365000000>;
			opp-microvolt = <910800>;
		};

		opp-238000000 {
			opp-hz = /bits/ 64 <238000000>;
			opp-microvolt = <859500>;
		};
	};

	/* CONSYS on MT6797: CONN2AP sleep mask at MCU +0x1350, AP2CONN
	 * oscillator control at topckgen +0x1f00 and the top AXI protection
	 * at +0x1220/+0x1228. */
	connsys: connsys@18070000 {
		compatible = "mediatek,mt6797-connsys";
		reg = <0 0x18070000 0 0x1000>,
		      <0 0x10007000 0 0x1000>,
		      <0 0x10000000 0 0x1000>,
		      <0 0x10006000 0 0x1000>,
		      <0 0x18070000 0 0x1000>,
		      <0 0x1100c000 0 0x1000>,
		      <0 0x11000780 0 0x80>,
		      <0 0x11000800 0 0x80>;
		reg-names = "mcu", "ap_rgu", "topckgen", "spm", "axi",
			    "btif", "btif_tx_dma", "btif_rx_dma";
		interrupts = <GIC_SPI 90 IRQ_TYPE_LEVEL_LOW>,
			     <GIC_SPI 90 IRQ_TYPE_LEVEL_LOW>,
			     <GIC_SPI 111 IRQ_TYPE_LEVEL_LOW>,
			     <GIC_SPI 112 IRQ_TYPE_LEVEL_LOW>;
		interrupt-names = "btif", "btif_tx_dma", "btif_rx_dma";
		clocks = <&infrasys CLK_INFRA_BTIF>;
		clock-names = "btif";
		mediatek,connsys-chip-id = <0x6797>;
		status = "disabled";
	};

};
